AUTOSAR XML (schema 00048)
package /MICROSAR/StbM_swc/ComponentTypes
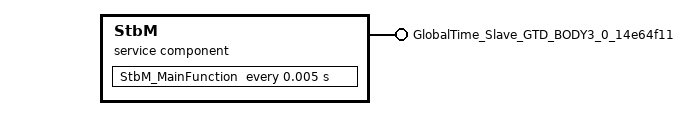
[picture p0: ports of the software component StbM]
  service sw component type StbM: category=SERVICE_COMPONENT
    provide port GlobalTime_Slave_GTD_BODY3_0_14e64f11: provided-interface=GlobalTime_Slave_GTD_BODY3_0_14e64f11
    behavior StbMInternalBehavior:
      handle-termination-and-restart=NO-SUPPORT
      included-data-type-set=data-type=[StbM_SynchronizedTimeBaseType, StbM_TimeBaseStatusType, StbM_TimeStampType, StbM_UserDataType, StbM_RateDeviationType, StbM_SyncRecordTableHeadType, StbM_SyncRecordTableBlockType, StbM_OffsetRecordTableHeadType, StbM_OffsetRecordTableBlockType, StbM_PortIdType, StbM_TimeStampShortType, StbM_VirtualLocalTimeType, StbM_EthTimeMasterMeasurementType, StbM_EthTimeSlaveMeasurementType, StbM_PdelayInitiatorMeasurementType, StbM_PdelayResponderMeasurementType, StbM_TimeDiffType, StbM_TimeBaseNotificationType, StbM_CustomerIdType, StbM_MasterConfigType]
      port-api-option{enable-take-address=true, indirect-api=false, port-defined-argument-value{value=0, value-type=StbM_SynchronizedTimeBaseType}, port=GlobalTime_Slave_GTD_BODY3_0_14e64f11}
      timing event Timer_StbM_MainFunction: start-on-event=StbM_MainFunction, period=0.005
      4 x operation invoked event:
        OpEventGetCurrentTime_GetCurrentTime_GlobalTime_Slave_GTD_BODY3_0_14e64f11: start-on-event=GetCurrentTime, operation=GlobalTime_Slave_GTD_BODY3_0_14e64f11.GetCurrentTime
        OpEventGetRateDeviation_GetRateDeviation_GlobalTime_Slave_GTD_BODY3_0_14e64f11: start-on-event=GetRateDeviation, operation=GlobalTime_Slave_GTD_BODY3_0_14e64f11.GetRateDeviation
        OpEventGetTimeLeap_GetTimeLeap_GlobalTime_Slave_GTD_BODY3_0_14e64f11: start-on-event=GetTimeLeap, operation=GlobalTime_Slave_GTD_BODY3_0_14e64f11.GetTimeLeap
        OpEventGetTimeBaseStatus_GetTimeBaseStatus_GlobalTime_Slave_GTD_BODY3_0_14e64f11: start-on-event=GetTimeBaseStatus, operation=GlobalTime_Slave_GTD_BODY3_0_14e64f11.GetTimeBaseStatus
      5 x runnable:
        StbM_MainFunction
        GetCurrentTime: can-be-invoked-concurrently=true, symbol=StbM_GetCurrentTime
        GetRateDeviation: can-be-invoked-concurrently=true, symbol=StbM_GetRateDeviation
        GetTimeLeap: can-be-invoked-concurrently=true, symbol=StbM_GetTimeLeap
        GetTimeBaseStatus: can-be-invoked-concurrently=true, symbol=StbM_GetTimeBaseStatus
  swc implementation StbMImplementation: programming-language=C, behavior=StbMInternalBehavior
